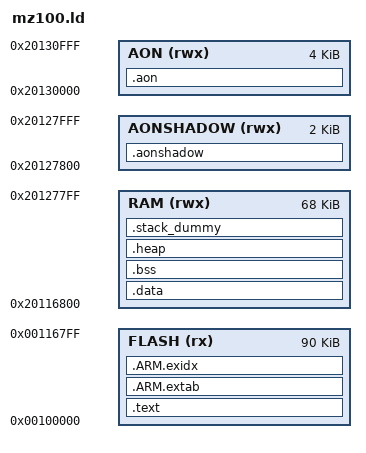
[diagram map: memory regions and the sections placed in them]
SEARCH_DIR(.)
GROUP(-lgcc -lc -lnosys)

MEMORY
{
  FLASH (rx) : ORIGIN = 0x100000, LENGTH = 90k
  RAM (rwx) :  ORIGIN = 0x20100000 + 90k, LENGTH = 160k - 90k - 2k
  AONSHADOW (rwx) : ORIGIN =   0x20128000 - 2k, LENGTH = 2k
  AON (rwx) : ORIGIN = 0x20130000 , LENGTH = 4k
}

ENTRY(Reset_Handler)

SECTIONS
{
    .text :
    {
        KEEP(*(.isr_vector))
        KEEP(*(.ver))
        KEEP(*(.default_mac))
        *(.text*)

        KEEP(*(.init))
        KEEP(*(.fini))

        /* .ctors */
        *crtbegin.o(.ctors)
        *crtbegin?.o(.ctors)
        *(EXCLUDE_FILE(*crtend?.o *crtend.o) .ctors)
        *(SORT(.ctors.*))
        *(.ctors)

        /* .dtors */
        *crtbegin.o(.dtors)
        *crtbegin?.o(.dtors)
        *(EXCLUDE_FILE(*crtend?.o *crtend.o) .dtors)
        *(SORT(.dtors.*))
        *(.dtors)

        *(.rodata*)

        KEEP(*(.eh_frame*))
    } > FLASH
    
    .ARM.extab : 
    {
        *(.ARM.extab* .gnu.linkonce.armextab.*)
    } > FLASH

    __exidx_start = .;
    .ARM.exidx :
    {
        *(.ARM.exidx* .gnu.linkonce.armexidx.*)
    } > FLASH
    __exidx_end = .;

    __etext = .;
        
    .data : AT (__etext)
    {
        __data_start__ = .;
        *(vtable)
        *(.data*)

        . = ALIGN(4);
        /* preinit data */
        PROVIDE_HIDDEN (__preinit_array_start = .);
        KEEP(*(.preinit_array))
        PROVIDE_HIDDEN (__preinit_array_end = .);

        . = ALIGN(4);
        /* init data */
        PROVIDE_HIDDEN (__init_array_start = .);
        KEEP(*(SORT(.init_array.*)))
        KEEP(*(.init_array))
        PROVIDE_HIDDEN (__init_array_end = .);


        . = ALIGN(4);
        /* finit data */
        PROVIDE_HIDDEN (__fini_array_start = .);
        KEEP(*(SORT(.fini_array.*)))
        KEEP(*(.fini_array))
        PROVIDE_HIDDEN (__fini_array_end = .);

        KEEP(*(.jcr*))
        . = ALIGN(4);
        /* All data end */
        __data_end__ = .;

    } > RAM

    .bss :
    {
        . = ALIGN(4);
        __bss_start__ = .;
        *(.bss*)
        *(COMMON)
        . = ALIGN(4);
        __bss_end__ = .;
    } > RAM
    
    .heap (COPY):
    {
        __end__ = .;
        PROVIDE(end = .);
        *(.heap*)
        __HeapLimit = .;
    } > RAM

    /* .stack_dummy section doesn't contains any symbols. It is only
     * used for linker to calculate size of stack sections, and assign
     * values to stack symbols later */
    .stack_dummy (COPY):
    {
        *(.stack*)
    } > RAM

    /* Set stack top to end of RAM, and stack limit move down by
     * size of stack_dummy section */
    __StackTop = ORIGIN(RAM) + LENGTH(RAM);
    __StackLimit = __StackTop - SIZEOF(.stack_dummy);
    PROVIDE(__stack = __StackTop);
    
    /* Check if data + heap + stack exceeds RAM limit */
    ASSERT(__StackLimit >= __HeapLimit, "region RAM overflowed with stack")

.aon (NOLOAD):
  {
        . = ALIGN(4);
		_start_of_aon = .;
	*(.aon)
	*(.aon.*)
        . = ALIGN(4);
		_end_of_aon = .;

  } > AON
.aonshadow (NOLOAD):
  {
        . = ALIGN(4);
                _start_of_aonshadow = .;
        *(.aonshadow)
        *(.aonshadow.*)
        . = ALIGN(4);
                _end_of_aonshadow = .;

  } > AONSHADOW
}


